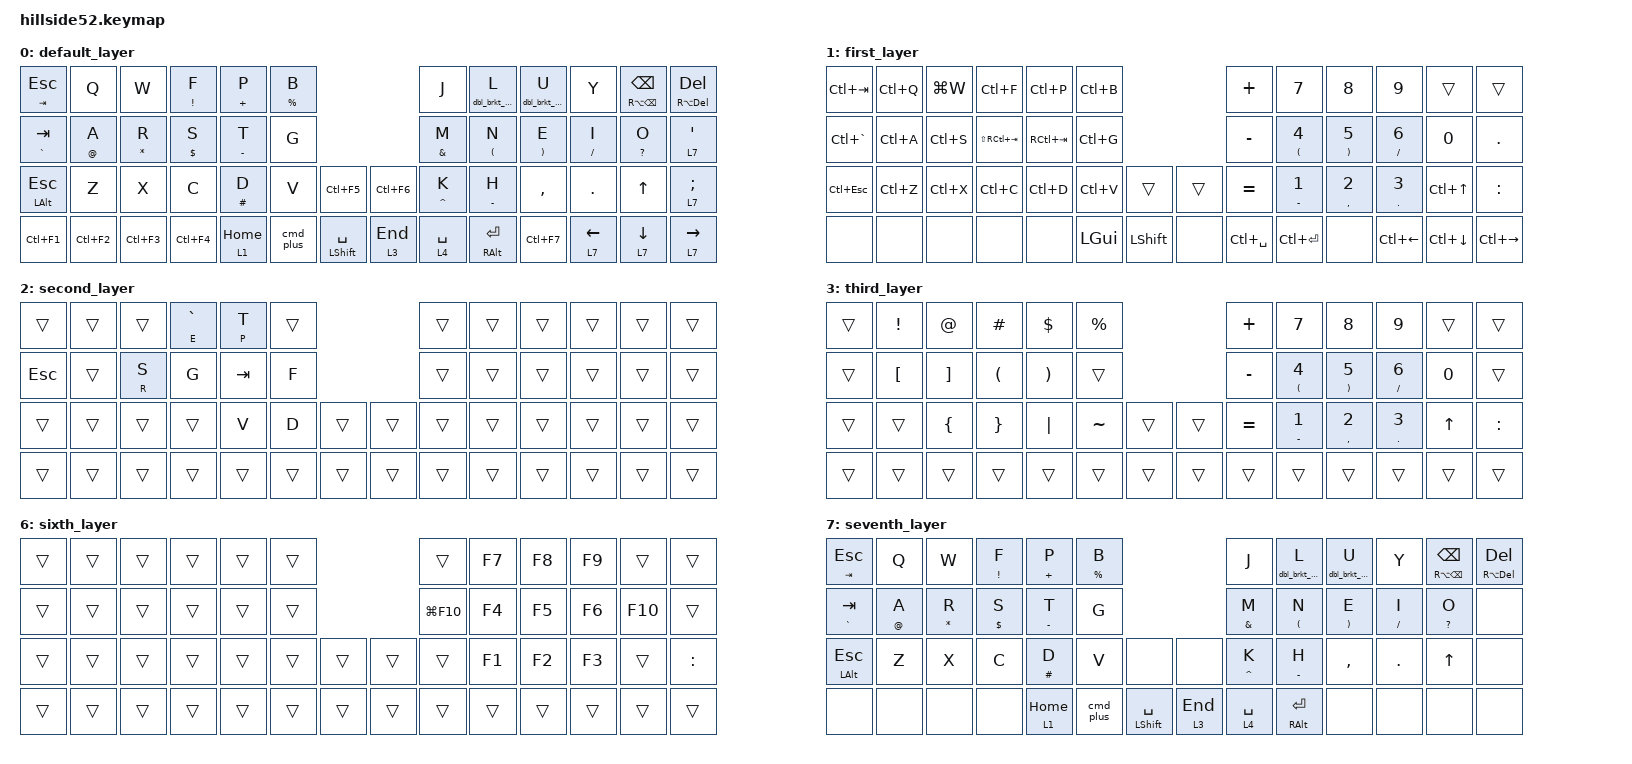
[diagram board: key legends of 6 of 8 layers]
/*
 * Copyright (c) 2021-2022 The ZMK Contributors
 *
 * SPDX-License-Identifier: MIT
 */

#include <behaviors.dtsi>
#include <dt-bindings/zmk/bt.h>
#include <dt-bindings/zmk/ext_power.h>
#include <dt-bindings/zmk/keys.h>
#include <dt-bindings/zmk/outputs.h>

#define COMBO(NAME, BINDINGS, KEYPOS, LAYERS) \
  combo_##NAME { \
    timeout-ms = <75>; \
    bindings = <BINDINGS>; \
    key-positions = <KEYPOS>; \
    layers = <LAYERS>; \
  };

/ {
    combos {
        compatible = "zmk,combos";
  
        COMBO(one, &kp ESC, 0 1, 0 1 2 3 4 5 6)
        COMBO(three, &kp DEL, 10 11, 0 1 2 3 4 5 6)
        COMBO(six, &kp C_VOL_UP, 46 47, 0 1 2 3 4 5 6)
        COMBO(seven, &kp C_VOL_DN, 45 46, 0 1 2 3 4 5 6)
        COMBO(eightA, &kp C_PP, 35 36, 0 1 2 3 4 5 6)         // play/pause
        COMBO(eightB, &kp C_PP, 47 48, 0 1 2 3 4 5 6)         // also play/pause
        COMBO(nine, &kp C_BRI_UP, 6 7, 0 1 2 3 4 5 6)
        COMBO(ten, &kp C_BRI_DN, 18 19, 0 1 2 3 4 5 6)
        COMBO(eleven, &mo 5, 1 2 3 4, 0 1 2 3 4 5 6)          // holding down all 4 left hand keys above home row > layer 5
        COMBO(twelve, &mo 6, 42 43, 0 1 2 3 4 5 6)            // hold down first 2 thumb keys for layer 6 (F keys)
        COMBO(reset_to_flash_firmware, &bootloader, 38 39 40, 0 1 2 3 4 5 6)        // press lower left 3 keys to reset keyboard (to flash firmware)
        COMBO(thirteen, &kp F13, 33 34, 0 1 2 3 4 5 6)         // h and , (bottom row right hand index middle fingers) = F13 (triggers BTT rewind in Vivaldi)
        COMBO(fourteen, &kp F14, 34 35, 0 1 2 3 4 5 6)         // , and . (bottom row right hand middle and ring fingers) = F14 (triggered by BTT fastforward in Vivaldi)
        COMBO(fifteen, &kp F15, 26 27, 0 1 2 3 4 5 6)          // bottom row, left hand ring & middle; copies heading embed link (configured in obsidian settings)
        COMBO(sixteen, &kp F16, 27 28, 0 1 2 3 4 5 6)          // bottom row, left hand middle & index; pastes heading embed link (configured in obsidian settings)
        COMBO(note, &kp F17, 43 46, 0 1 2 3 4 5 6)             // L and R middle thumbs (same keys for spotlight/cmd space); activates spontaneous shortcut (configured in btt keyboard shortcut settings)
        COMBO(YTnote, &kp F18, 44 45, 0 1 2 3 4 5 6)           // L and R upper/innermost thumbs; activates yt note shortcut (configured in btt keyboard shortcut settings)
        COMBO(singlenote, &kp F19, 42 47, 0 1 2 3 4 5 6)       // L and R outer thumbs (second to outermost thumbs); activates append only one note shortcut (configured in btt keyboard shortcut settings)
        COMBO(commandshift, &cmd_shft, 43 44, 0 1 2 3 4 5 6)   // middle and right buttons for left thumb activate command shift
    };

    mp: medium-long-press {
        compatible = "zmk,behavior-hold-tap";
        label = "MEDIUM_LONG_PRESS";
        #binding-cells = <2>;
        flavor = "tap-preferred";
        tapping-term-ms = <200>;
        quick-tap-ms = <125>;
        global-quick-tap;
        bindings = <&kp>, <&kp>;
    };

    lp: long-press {
        compatible = "zmk,behavior-hold-tap";
        label = "LONG_PRESS";
        #binding-cells = <2>;
        flavor = "tap-preferred";
        tapping-term-ms = <250>;
        quick-tap-ms = <125>;
        global-quick-tap;
        bindings = <&kp>, <&kp>;
    };

db: double-bracket {
    compatible = "zmk,behavior-hold-tap";
    label = "DOUBLE_BRACKET";
    #binding-cells = <2>;
    flavor = "tap-preferred";
    tapping-term-ms = <300>;
    quick-tap-ms = <125>;
    global-quick-tap;
    bindings = <&dbl_brkt_open>, <&kp>;
};

eb: close-double-bracket {
    compatible = "zmk,behavior-hold-tap";
    label = "CLOSE_DOUBLE_BRACKET";
    #binding-cells = <2>;
    flavor = "tap-preferred";
    tapping-term-ms = <300>;
    quick-tap-ms = <125>;
    global-quick-tap;
    bindings = <&dbl_brkt_close>, <&kp>;
};

    macros {
        ctrl_shift: ctrl_shift {
            label = "ctrl_shift";
            compatible = "zmk,behavior-macro";
            #binding-cells = <0>;
            wait-ms = <0>;
            bindings
                = <&macro_press &kp LSHIFT &kp LCTRL>
                , <&macro_pause_for_release>
                , <&macro_release &kp LSHIFT &kp LCTRL>;
        };
        ctrl_plus: ctrl_plus {
            label = "ctrl_plus";
            compatible = "zmk,behavior-macro";
            #binding-cells = <0>;
            wait-ms = <0>;
            bindings
                = <&macro_press &mo 1 &kp LCTRL>
                , <&macro_pause_for_release>
                , <&macro_release &mo 1 &kp LCTRL>;
        };
        cmd_plus: cmd_plus {
            label = "cmd_plus";
            compatible = "zmk,behavior-macro";
            #binding-cells = <0>;
            wait-ms = <0>;
            bindings
                = <&macro_press &mo 2 &kp LGUI>
                , <&macro_pause_for_release>
                , <&macro_release &mo 2 &kp LGUI>;
        };
        alt_space: alt_space {
            label = "alt_space";
            compatible = "zmk,behavior-macro";
            #binding-cells = <0>;
            wait-ms = <0>;
            bindings
                = <&macro_press &mo 1 &kp RALT>
                , <&macro_pause_for_release>
                , <&macro_release &mo 1 &kp RALT>;
        };
        dbl_brkt_open: dbl_brkt_open {
            label = "dbl_brkt_open";
            compatible = "zmk,behavior-macro";
            #binding-cells = <0>;
            wait-ms = <0>;
            bindings
                = <&macro_press &kp LBKT &kp LBKT>
                , <&macro_pause_for_release>
                , <&macro_release &kp LBKT &kp LBKT>;
        };
        dbl_brkt_close: dbl_brkt_close {
            label = "dbl_brkt_close";
            compatible = "zmk,behavior-macro";
            #binding-cells = <0>;
            wait-ms = <0>;
            bindings
                = <&macro_press &kp RBKT &kp RBKT>
                , <&macro_pause_for_release>
                , <&macro_release &kp RBKT &kp RBKT>;
        };
        cmd_shft:  cmd_shft {
            label = "cmd_shft";
            compatible = "zmk,behavior-macro";
            #binding-cells = <0>;
            wait-ms = <0>;
            bindings
                = <&macro_press &kp LGUI &kp LSHIFT>
                , <&macro_pause_for_release>
                , <&macro_release &kp LGUI &kp LSHIFT>;
        };
    };

    behaviors {
        gres: grave_escap {
            compatible = "zmk,behavior-mod-morph";
            label = "GRAVE_ESCAP";
            #binding-cells = <0>;
            bindings = <&kp V>, <&kp LSHIFT>;
            mods = <(MOD_LCTL)>;
        };
    };

    behaviors {
        td0: tap_dance_0 {
            compatible = "zmk,behavior-tap-dance";
            #binding-cells = <0>;
            tapping-term-ms = <250>;
            bindings = <&kp J>, <&dbl_brkt_open>;
        };
    };

        keymap {
                compatible = "zmk,keymap";

                default_layer {
/* QWERTY
 * -------------------------------------------------------------------------------------------------------------------------------------
 * | `     |   Q   |   W   |   E   |   R   |   T   |-----------------------------------|   Y   |   U   |   I   |   O   |   P   | BKSPC |
 * | TAB   |   A   |   S   |   D   |   F   |   G   |-----------------------------------|   H   |   J   |   K   |   L   |   ;   | ENTER |
 * | SHIFT |   Z   |   X   |   C   |   V   |   B   |   '   |-------------------|   /   |   N   |   M   |   ,   |   .   |  Up   | SHIFT |
 * | Mute  |  ESC  | CTRL  |-------|  GUI  |  ALT  |SK SHFT|  Nav  |---|  Sym  | SPACE |  ALT  |  GUI  |-------| Left  | Down  | Right |
 */

/* QWERTY
 * ------------------------------------------------------------------------------------------------------------------------------------------------          
 * |  00   |   01   |   02   |   03   |   04   |   05   |-----------------------------------|   06   |   07   |   08   |   09   |   10   |   11   |
 * |  12   |   13   |   14   |   15   |   16   |   17   |-----------------------------------|   18   |   19   |   20   |   21   |   22   |   23   |
 * |  24   |   25   |   26   |   27   |   28   |   29   |   30   |-----------------|   31   |   32   |   33   |   34   |   35   |   36   |   37   |
 * |  38   |   39   |   40   |   41   |   42   |   43   |   44   |-----------------|   45   |   46   |   47   |   48   |   49   |   50   |   51   |
 */

// --------------------------------------------------------------------------------------------------------------------
// |   0-TAB |   1-Q  |   2-W  |   3-E  |   4-R  |   5-T  |   |   6-Y  |   7-U   |   8-I  |   9-O  |  10-P  | 11-BKSP |
// | 12-CTRL |  13-A  |  14-S  |  15-D  |  16-F  |  17-G  |   |  18-H  |  19-J   |  20-K  |  21-L  |  22-;  |  23-'   |
// | 24-SHFT |  25-Z  |  26-X  |  27-C  |  28-V  |  29-B  |   |  30-N  |  31-M   |  32-,  |  33-.  |  34-/  | 35-ESC  |
//                             | 36-GUI | 37-LWR | 38-SPC |   | 39-ENT | 40-RSE  | 41-ALT |

                        bindings = < 
//  _____________________________________________________________________________                                _____________________________________________________________________________
// |      0     |     1      |     2      |      3     |      4     |      5     |                              |     6      |     7      |     8      |     9      |     10     |     11     |           
     &lp TAB ESC    &kp Q        &kp W      &mp EXCL F   &lp PLUS P   &lp PRCNT B                                    &kp J      &db 0 L      &eb 0 U      &kp Y    &mp RA(BSPC) BSPC  &mp RA(DEL) DEL
// |____________|____________|____________|____________|____________|____________|                              |____________|____________|____________|____________|____________|____________|
// |     12     |     13     |     14     |     15     |     16     |     17     |                              |     18     |     19     |     20     |     21     |     22     |     23     |           
   &lp GRAVE TAB   &lp AT A    &lp STAR R   &lp DLLR S   &mp MINUS T     &kp G                                     &mp AMPS M   &mp LPAR N   &mp RPAR E   &mp SLASH I  &lp QMARK O  &lt 7 SQT
// |____________|____________|____________|____________|____________|____________|____________      ____________|____________|____________|____________|____________|____________|____________|
// |     24     |     25     |     26     |     27     |     28     |     29     |    30 T    |    |    31 T    |     32     |     33     |     34     |     35     |     36     |     37     |           
    &mp LALT ESC    &kp Z        &kp X       &kp C       &mp HASH D     &kp V      &kp LC(F5)        &kp LC(F6)  &mp CARET K  &mp MINUS H    &kp COMMA     &kp DOT       &kp UP     &lt 7 SEMI
// |____________|____________|____________|____________|____________|____________|____________|    |____________|____________|____________|____________|____________|____________|____________|
// |     38     |     39     |     40     |    41 T1   |    42 T2   |    43 T3   |    44 T4   |    |   45 T1    |   46 T2    |   47 T3    |   48 T4    |     49     |     50     |     51     |           
     &kp LC(F1)   &kp LC(F2)   &kp LC(F3)   &kp LC(F4)   &lt 1 HOME   &cmd_plus   &mt LSHIFT SPACE  &lt 3 END    &lt 4 SPACE  &mt RALT RET  &kp LC(F7)   &lt 7 LEFT   &lt 7 DOWN   &lt 7 RIGHT
// |____________|____________|____________|____________|____________|____________|____________|    |____________|____________|____________|____________|____________|____________|____________|
                        >;
                };

                first_layer {
                        bindings = <
//  _____________________________________________________________________________        1. LEFT THUMB 1         _____________________________________________________________________________
// |      0     |     1      |     2      |      3     |      4     |      5     |                              |     6      |     7      |     8      |     9      |     10     |     11     |           
    &kp LC(TAB)   &kp LC(Q)   &kp LG(W)    &kp LC(F)    &kp LC(P)    &kp LC(B)                                     &kp PLUS     &kp N7       &kp N8       &kp N9        &trans       &trans
// |____________|____________|____________|____________|____________|____________|                              |____________|____________|____________|____________|____________|____________|
// |     12     |     13     |     14     |     15     |     16     |     17     |                              |     18     |     19     |     20     |     21     |     22     |     23     |           
   &kp LC(GRAVE) &kp LC(A)    &kp LC(S)   &kp LS(RC(TAB)) &kp RC(TAB)  &kp LC(G)                                 &kp MINUS    &mp LPAR N4  &mp RPAR N5  &mp SLASH N6    &kp N0      &kp DOT
// |____________|____________|____________|____________|____________|____________|____________      ____________|____________|____________|____________|____________|____________|____________|
// |     24     |     25     |     26     |     27     |     28     |     29     |    30 T    |    |    31 T    |     32     |     33     |     34     |     35     |     36     |     37     |           
    &kp LC(ESC)  &kp LC(Z)    &kp LC(X)    &kp LC(C)    &kp LC(D)    &kp LC(V)       &trans            &trans      &kp EQUAL  &mp MINUS N1 &mp COMMA N2  &mp DOT N3   &kp LC(UP)    &kp COLON
// |____________|____________|____________|____________|____________|____________|____________|    |____________|____________|____________|____________|____________|____________|____________|
// |     38     |     39     |     40     |    41 T1   |    42 T2   |    43 T3   |    44 T4   |    |   45 T1    |   46 T2    |   47 T3    |   48 T4    |     49     |     50     |     51     |           
      &none         &none        &none        &none       &none      &kp LGUI     &kp LSHIFT           &none     &kp LC(SPACE) &kp LC(RET)    &none     &kp LC(LEFT) &kp LC(DOWN) &kp LC(RIGHT)
// |____________|____________|____________|____________|____________|____________|____________|    |____________|____________|____________|____________|____________|____________|____________|
                        >;
                };

                second_layer {
                        bindings = <
//  _____________________________________________________________________________        2. LEFT THUMB 2         _____________________________________________________________________________
// |      0     |     1      |     2      |      3     |      4     |      5     |                              |     6      |     7      |     8      |     9      |     10     |     11     |            
    &trans       &trans       &trans       &mt E GRAVE   &mp P T      &trans                                        &trans       &trans       &trans       &trans       &trans       &trans
// |____________|____________|____________|____________|____________|____________|                              |____________|____________|____________|____________|____________|____________|
// |     12     |     13     |     14     |     15     |     16     |     17     |                              |     18     |     19     |     20     |     21     |     22     |     23     |           
      &kp ESC      &trans       &mp R S       &kp G       &kp TAB       &kp F                                      &trans        &trans       &trans       &trans       &trans       &trans
// |____________|____________|____________|____________|____________|____________|____________      ____________|____________|____________|____________|____________|____________|____________|
// |     24     |     25     |     26     |     27     |     28     |     29     |    30 T    |    |    31 T    |     32     |     33     |     34     |     35     |     36     |     37     |           
       &trans       &trans       &trans       &trans       &kp V        &kp D        &trans            &trans       &trans       &trans       &trans       &trans      &trans        &trans
// |____________|____________|____________|____________|____________|____________|____________|    |____________|____________|____________|____________|____________|____________|____________|
// |     38     |     39     |     40     |    41 T1   |    42 T2   |    43 T3   |    44 T4   |    |   45 T1    |   46 T2    |   47 T3    |   48 T4    |     49     |     50     |     51     |           
       &trans       &trans       &trans       &trans       &trans       &trans        &trans           &trans       &trans       &trans      &trans        &trans       &trans       &trans
// |____________|____________|____________|____________|____________|____________|____________|    |____________|____________|____________|____________|____________|____________|____________|
                        >;
                };


                third_layer { 
                        bindings = <
//  _____________________________________________________________________________        3. RIGHT THUMB 1        _____________________________________________________________________________
// |      0     |     1      |     2      |      3     |      4     |      5     |                              |     6      |     7      |     8      |     9      |     10     |     11     |     
     &trans       &kp EXCL     &kp AT       &kp HASH     &kp DLLR     &kp PRCNT                                    &kp PLUS      &kp N7       &kp N8       &kp N9       &trans       &trans
// |____________|____________|____________|____________|____________|____________|                              |____________|____________|____________|____________|____________|____________|
// |     12     |     13     |     14     |     15     |     16     |     17     |                              |     18     |     19     |     20     |     21     |     22     |     23     |           
     &trans       &kp LBKT     &kp RBKT     &kp LPAR     &kp RPAR     &trans                                      &kp MINUS   &mp LPAR N4  &mp RPAR N5  &mp SLASH N6    &kp N0       &trans
// |____________|____________|____________|____________|____________|____________|____________      ____________|____________|____________|____________|____________|____________|____________|
// |     24     |     25     |     26     |     27     |     28     |     29     |    30 T    |    |    31 T    |     32     |     33     |     34     |     35     |     36     |     37     |           
     &trans       &trans       &kp LBRC     &kp RBRC     &kp PIPE     &kp TILDE       &trans           &trans     &kp EQUAL   &mp MINUS N1 &mp COMMA N2  &mp DOT N3     &kp UP     &kp COLON
// |____________|____________|____________|____________|____________|____________|____________|    |____________|____________|____________|____________|____________|____________|____________|
// |     38     |     39     |     40     |    41 T1   |    42 T2   |    43 T3   |    44 T4   |    |   45 T1    |   46 T2    |   47 T3    |   48 T4    |     49     |     50     |     51     |
       &trans       &trans       &trans       &trans       &trans       &trans        &trans           &trans       &trans       &trans      &trans        &trans       &trans       &trans
// |____________|____________|____________|____________|____________|____________|____________|    |____________|____________|____________|____________|____________|____________|____________|
                        >;
                };

                fourth_layer {
                        bindings = <
//  _____________________________________________________________________________        4. RIGHT THUMB 2        _____________________________________________________________________________
// |      0     |     1      |     2      |      3     |      4     |      5     |                              |     6      |     7      |     8      |     9      |     10     |     11     |         
     &trans        &trans       &trans       &trans       &trans       &trans                                    &lp RG(J) J  &lp RG(L) L  &lp RG(U) U  &lp RG(Y) Y  &kp RG(BSPC) &kp RG(DEL)
// |____________|____________|____________|____________|____________|____________|                              |____________|____________|____________|____________|____________|____________|
// |     12     |     13     |     14     |     15     |     16     |     17     |                              |     18     |     19     |     20     |     21     |     22     |     23     |           
     &trans        &trans       &trans       &trans       &trans       &trans                                    &lp RG(M) M  &lp RG(N) N  &lp RG(E) E  &lp RG(I) I  &lp RG(O) (O) &trans
// |____________|____________|____________|____________|____________|____________|____________      ____________|____________|____________|____________|____________|____________|____________|
// |     24     |     25     |     26     |     27     |     28     |     29     |    30 T    |    |    31 T    |     32     |     33     |     34     |     35     |     36     |     37     |           
       &trans       &trans       &trans       &trans       &trans       &trans        &trans           &trans    &lp RG(K) K  &lp RG(H) H     &trans       &trans     &kp RG(UP)     &trans
// |____________|____________|____________|____________|____________|____________|____________|    |____________|____________|____________|____________|____________|____________|____________|
// |     38     |     39     |     40     |    41 T1   |    42 T2   |    43 T3   |    44 T4   |    |   45 T1    |   46 T2    |   47 T3    |   48 T4    |     49     |     50     |     51     |
       &trans       &trans       &trans       &trans       &trans       &trans        &trans           &trans       &trans       &trans      &trans     &kp RG(LEFT) &kp RG(DOWN) &kp RG(RIGHT)
// |____________|____________|____________|____________|____________|____________|____________|    |____________|____________|____________|____________|____________|____________|____________|
                        >;
                };

                fifth_layer { 
                        bindings = <
//  _____________________________________________________________________________       5. Keys 1-4 (&mo 5)      _____________________________________________________________________________
// |      0     |     1      |     2      |      3     |      4     |      5     |                              |     6      |     7      |     8      |     9      |     10     |     11     |     
    &trans       &trans       &trans       &trans       &trans       &trans                                      &trans       &trans       &trans       &trans       &trans       &trans
// |____________|____________|____________|____________|____________|____________|                              |____________|____________|____________|____________|____________|____________|
// |     12     |     13     |     14     |     15     |     16     |     17     |                              |     18     |     19     |     20     |     21     |     22     |     23     |      
    &trans       &trans       &trans       &trans       &trans       &trans                                      &bt BT_CLR &bt BT_SEL 0 &bt BT_SEL 1 &bt BT_SEL 2 &bt BT_SEL 3 &bt BT_SEL 4
// |____________|____________|____________|____________|____________|____________|____________      ____________|____________|____________|____________|____________|____________|____________|
// |     24     |     25     |     26     |     27     |     28     |     29     |    30 T    |    |    31 T    |     32     |     33     |     34     |     35     |     36     |     37     |  
    &trans       &trans       &trans       &trans       &trans       &trans                                      &trans       &trans       &trans       &trans       &trans       &trans
// |____________|____________|____________|____________|____________|____________|____________|    |____________|____________|____________|____________|____________|____________|____________|
// |     38     |     39     |     40     |    41 T1   |    42 T2   |    43 T3   |    44 T4   |    |   45 T1    |   46 T2    |   47 T3    |   48 T4    |     49     |     50     |     51     |
       &trans       &trans       &trans       &trans       &trans       &trans        &trans           &trans       &trans       &trans      &trans        &trans       &trans       &trans
// |____________|____________|____________|____________|____________|____________|____________|    |____________|____________|____________|____________|____________|____________|____________|
                        >;
                };
                
                sixth_layer { 
                        bindings = <
//  _____________________________________________________________________________       6. Keys 42-43 (&mo 6)    _____________________________________________________________________________
// |      0     |     1      |     2      |      3     |      4     |      5     |                              |     6      |     7      |     8      |     9      |     10     |     11     |    
      &trans       &trans       &trans       &trans       &trans       &trans                                      &trans        &kp F7       &kp F8       &kp F9       &trans       &trans
// |____________|____________|____________|____________|____________|____________|                              |____________|____________|____________|____________|____________|____________|
// |     12     |     13     |     14     |     15     |     16     |     17     |                              |     18     |     19     |     20     |     21     |     22     |     23     |  
      &trans       &trans       &trans       &trans       &trans       &trans                                     &kp LG(F10)    &kp F4       &kp F5       &kp F6       &kp F10      &trans
// |____________|____________|____________|____________|____________|____________|____________      ____________|____________|____________|____________|____________|____________|____________|
// |     24     |     25     |     26     |     27     |     28     |     29     |    30 T    |    |    31 T    |     32     |     33     |     34     |     35     |     36     |     37     |  
       &trans       &trans       &trans       &trans       &trans       &trans        &trans           &trans       &trans       &kp F1       &kp F2       &kp F3       &trans     &kp COLON
// |____________|____________|____________|____________|____________|____________|____________|    |____________|____________|____________|____________|____________|____________|____________|
// |     38     |     39     |     40     |    41 T1   |    42 T2   |    43 T3   |    44 T4   |    |   45 T1    |   46 T2    |   47 T3    |   48 T4    |     49     |     50     |     51     |
       &trans       &trans       &trans       &trans       &trans       &trans        &trans           &trans       &trans       &trans       &trans       &trans       &trans       &trans
// |____________|____________|____________|____________|____________|____________|____________|    |____________|____________|____________|____________|____________|____________|____________|
                        >;
                };

                seventh_layer { 
                        bindings = <
//  _____________________________________________________________________________                                _____________________________________________________________________________
// |      0     |     1      |     2      |      3     |      4     |      5     |                              |     6      |     7      |     8      |     9      |     10     |     11     |           
     &lp TAB ESC    &kp Q        &kp W      &mp EXCL F   &lp PLUS P   &lp PRCNT B                                    &kp J      &db 0 L      &eb 0 U      &kp Y    &mp RA(BSPC) BSPC  &mp RA(DEL) DEL
// |____________|____________|____________|____________|____________|____________|                              |____________|____________|____________|____________|____________|____________|
// |     12     |     13     |     14     |     15     |     16     |     17     |                              |     18     |     19     |     20     |     21     |     22     |     23     |           
   &lp GRAVE TAB   &lp AT A    &lp STAR R   &lp DLLR S   &mp MINUS T     &kp G                                     &mp AMPS M   &mp LPAR N   &mp RPAR E   &mp SLASH I  &lp QMARK O   &none
// |____________|____________|____________|____________|____________|____________|____________      ____________|____________|____________|____________|____________|____________|____________|
// |     24     |     25     |     26     |     27     |     28     |     29     |    30 T    |    |    31 T    |     32     |     33     |     34     |     35     |     36     |     37     |           
    &mp LALT ESC  &kp Z        &kp X       &kp C         &mp HASH D   &kp V          &none             &none    &mp CARET K  &mp MINUS H    &kp COMMA     &kp DOT       &kp UP       &none
// |____________|____________|____________|____________|____________|____________|____________|    |____________|____________|____________|____________|____________|____________|____________|
// |     38     |     39     |     40     |    41 T1   |    42 T2   |    43 T3   |    44 T4   |    |   45 T1    |   46 T2    |   47 T3    |   48 T4    |     49     |     50     |     51     |           
      &none         &none        &none        &none     &lt 1 HOME   &cmd_plus   &mt LSHIFT SPACE  &lt 3 END    &lt 4 SPACE  &mt RALT RET    &none         &none         &none       &none
// |____________|____________|____________|____________|____________|____________|____________|    |____________|____________|____________|____________|____________|____________|____________|
                        >;
                };
        };
};
